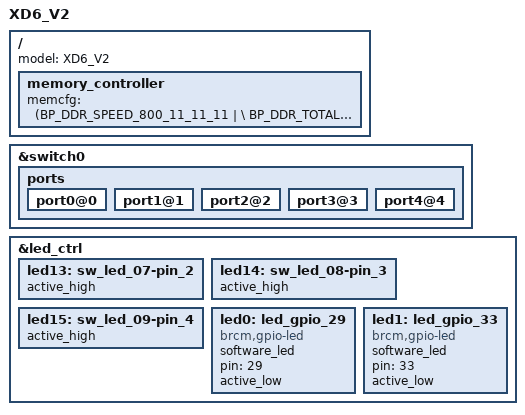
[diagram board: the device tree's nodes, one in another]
#include "63178.dtsi"

/ {
    model = "XD6_V2";

    memory_controller {
        memcfg = <(BP_DDR_SPEED_800_11_11_11 | \
                   BP_DDR_TOTAL_SIZE_512MB   | \
                   BP_DDR_DEVICE_WIDTH_16    | \
                   BP_DDR_TOTAL_WIDTH_16BIT  | \
                   BP_DDR_63178_DEFAULT)>;
    };
#if 0
	buttons {
		compatible = "brcm,buttons";
		reset_button {
			ext_irq = <&bca_extintr 0 BCA_GPIO_ACTIVE_LOW (BCA_EXTINTR_TYPE_LOW_LEVEL | BCA_EXTINTR_TYPE_SENSE_EDGE)>;
			press {
				print = "Button Press -- Hold for 5s to do restore to default";
			};
			hold {
				rst_to_dflt = <5>;
			};
			release {
				reset = <0>;
			};	
		};
		ses_button {
			ext_irq = <&bca_extintr 1 BCA_GPIO_ACTIVE_LOW (BCA_EXTINTR_TYPE_LOW_LEVEL | BCA_EXTINTR_TYPE_SENSE_EDGE)>;
			release {
				ses_short_period = <0>;
				ses_long_period = <3>;
			};
		};
	};
#endif
};

&switch0 {
	ports {
		port0@0 {
			status = "okay";
		};

		port1@1 {
			status = "okay";
		};

		port2@2 {
			status = "okay";
		};

		port3@3 {
			status = "okay";
		};

		port4@4 {
			status = "okay";
		};
	};
};

&led_ctrl {
	status = "okay";

	/* LED Group2 Red */
	led13: sw_led_07-pin_2 {
		active_high;
		status = "okay";
	};

	/* LED Group2 Green */
	led14: sw_led_08-pin_3 {
		active_high;
		status = "okay";
	};

	/* LED Group2 Blue */
	led15: sw_led_09-pin_4 {
		active_high;
		status = "okay";
	};

	/* BT RESET */
	 led0:led_gpio_29 {
		compatible = "brcm,gpio-led";
		software_led;
		pin = <29>;
		active_low;
	};

	/* BT DISABLE */
	led1:led_gpio_33 {
		compatible = "brcm,gpio-led";
		software_led;
		pin = <33>;
		active_low;
	};
};
